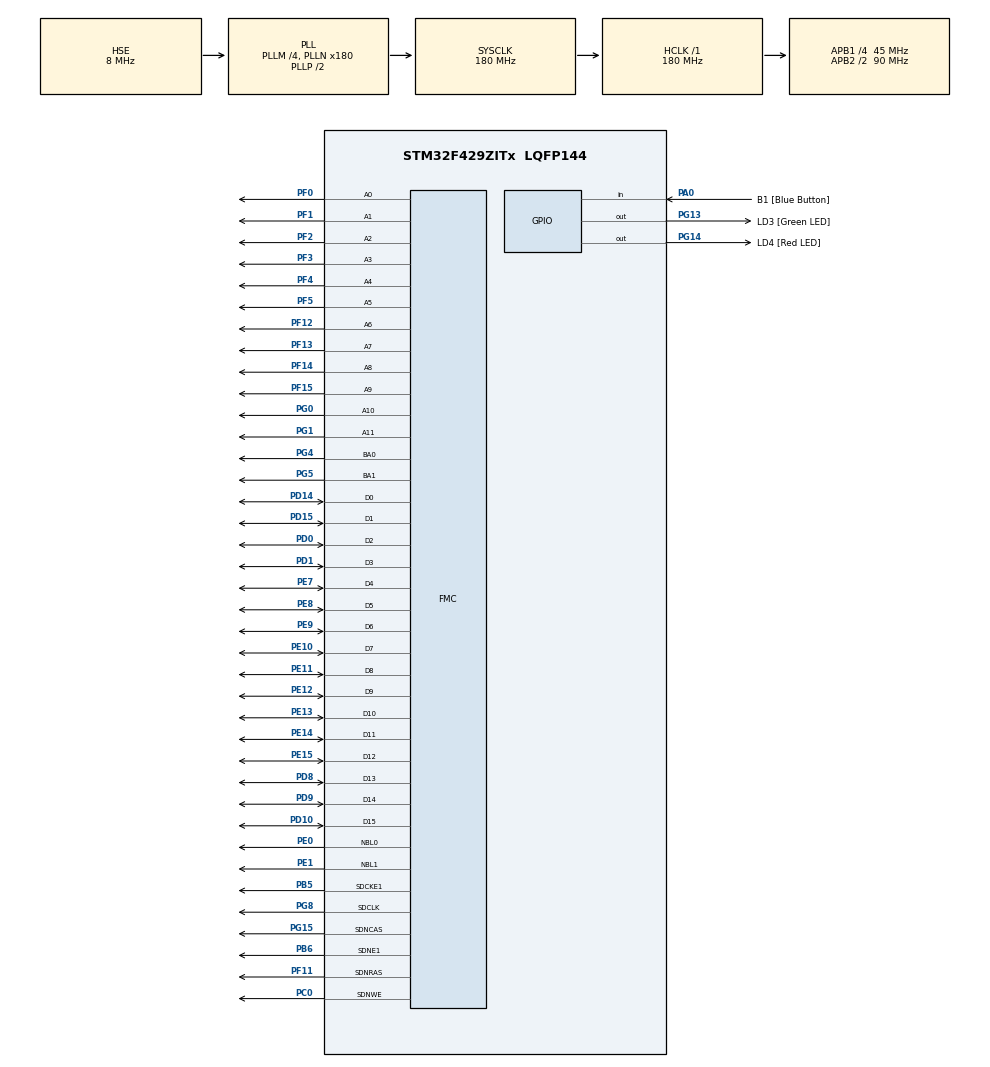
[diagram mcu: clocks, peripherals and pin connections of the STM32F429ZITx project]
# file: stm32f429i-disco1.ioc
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Mcu.Family=STM32F4
SH.FMC_D7_DA7.0=FMC_D7,sd-16b-d1
SH.FMC_A8.0=FMC_A8,12b-sda1
RCC.CortexFreq_Value=180000000
SH.FMC_A0.0=FMC_A0,12b-sda1
SH.FMC_D14_DA14.0=FMC_D14,sd-16b-d1
PG4.Signal=FMC_A14_BA0
PG8.Signal=FMC_SDCLK
PG0.Signal=FMC_A10
SH.FMC_NBL0.0=FMC_NBL0,Sd2ByteEnable1
SH.FMC_D6_DA6.0=FMC_D6,sd-16b-d1
VP_RTC_VS_RTC_Activate.Mode=RTC_Enabled
PA0/WKUP.Signal=GPIO_Input
PC14/OSC32_IN.Mode=LSE-External-Oscillator
SH.FMC_A14_BA0.0=FMC_BA0,FourSdramBanks1
SH.FMC_A11.0=FMC_A11,12b-sda1
SH.FMC_D5_DA5.0=FMC_D5,sd-16b-d1
PG13.Signal=GPIO_Output
PG15.Signal=FMC_SDNCAS
RCC.SYSCLKSource=RCC_SYSCLKSOURCE_PLLCLK
ProjectManager.StackSize=0x400
SH.FMC_A15_BA1.0=FMC_BA1,FourSdramBanks1
SH.FMC_D9_DA9.0=FMC_D9,sd-16b-d1
SH.FMC_A7.0=FMC_A7,12b-sda1
SH.FMC_SDNWE.0=FMC_SDNWE,12b-sda1
RCC.RCC_RTC_Clock_Source=RCC_RTCCLKSOURCE_LSE
PH0/OSC_IN.Mode=HSE-External-Clock-Source
SH.FMC_D11_DA11.0=FMC_D11,sd-16b-d1
RCC.HCLKFreq_Value=180000000
RCC.APB2TimFreq_Value=180000000
PB6.Signal=FMC_SDNE1
SH.FMC_NBL1.0=FMC_NBL1,Sd2ByteEnable1
PH1/OSC_OUT.Signal=RCC_OSC_OUT
PF12.Signal=FMC_A6
PB6.Mode=SdramChipSelect2_1
PD0.Signal=FMC_D2_DA2
PD8.Signal=FMC_D13_DA13
PE1.Signal=FMC_NBL1
SH.FMC_A10.0=FMC_A10,12b-sda1
RCC.AHBFreq_Value=180000000
RCC.HSE_VALUE=8000000
SH.FMC_D8_DA8.0=FMC_D8,sd-16b-d1
SH.FMC_D2_DA2.0=FMC_D2,sd-16b-d1
PE13.Signal=FMC_D10_DA10
PE9.Signal=FMC_D6_DA6
PA14.Mode=Serial_Wire
SH.FMC_A2.0=FMC_A2,12b-sda1
PF11.Signal=FMC_SDNRAS
PB5.Mode=SdramChipSelect2_1
SH.FMC_D1_DA1.0=FMC_D1,sd-16b-d1
PF3.Signal=FMC_A3
SH.FMC_SDNRAS.0=FMC_SDNRAS,12b-sda1
PH1/OSC_OUT.Mode=HSE-External-Clock-Source
PE10.Signal=FMC_D7_DA7
Mcu.Package=LQFP144
SH.FMC_D0_DA0.0=FMC_D0,sd-16b-d1
PC14/OSC32_IN.Signal=RCC_OSC32_IN
SH.FMC_A9.0=FMC_A9,12b-sda1
SH.FMC_D4_DA4.0=FMC_D4,sd-16b-d1
RCC.PLLSAIN=50
PF5.Signal=FMC_A5
SH.FMC_A1.0=FMC_A1,12b-sda1
RCC.APB2CLKDivider=RCC_HCLK_DIV2
SH.FMC_SDCLK.0=FMC_SDCLK,12b-sda1
PF14.Signal=FMC_A8
RCC.APB1TimFreq_Value=90000000
PF0.Signal=FMC_A0
PE7.Signal=FMC_D4_DA4
PD15.Signal=FMC_D1_DA1
SH.FMC_D3_DA3.0=FMC_D3,sd-16b-d1
RCC.PLLSourceVirtual=RCC_PLLSOURCE_HSE
SH.FMC_A4.0=FMC_A4,12b-sda1
PG1.Signal=FMC_A11
PG5.Signal=FMC_A15_BA1
SH.FMC_D10_DA10.0=FMC_D10,sd-16b-d1
PD1.Signal=FMC_D3_DA3
PD9.Signal=FMC_D14_DA14
PC0.Signal=FMC_SDNWE
RCC.APB1CLKDivider=RCC_HCLK_DIV4
PG13.GPIO_Label=LD3 [Green LED]
PD10.Signal=FMC_D15_DA15
PA13.Signal=SYS_JTMS-SWDIO
SH.FMC_A3.0=FMC_A3,12b-sda1
ProjectManager.TargetToolchain=STM32CubeIDE
SH.FMC_D15_DA15.0=FMC_D15,sd-16b-d1
SH.FMC_D13_DA13.0=FMC_D13,sd-16b-d1
PF2.Signal=FMC_A2
PE11.Signal=FMC_D8_DA8
PG14.Signal=GPIO_Output
board=custom
RCC.VCOOutputFreq_Value=360000000
PH0/OSC_IN.Signal=RCC_OSC_IN
SH.FMC_A6.0=FMC_A6,12b-sda1
RCC.APB2Freq_Value=90000000
PE14.Signal=FMC_D11_DA11
PE15.Signal=FMC_D12_DA12
PE8.Signal=FMC_D5_DA5
PA0/WKUP.GPIO_Label=B1 [Blue Button]
SH.FMC_D12_DA12.0=FMC_D12,sd-16b-d1
PF15.Signal=FMC_A9
PF13.Signal=FMC_A7
PF1.Signal=FMC_A1
PA13.Mode=Serial_Wire
PG14.GPIO_Label=LD4 [Red LED]
SH.FMC_SDNCAS.0=FMC_SDNCAS,12b-sda1
Mcu.Name=STM32F429ZITx
PE0.Signal=FMC_NBL0
PE12.Signal=FMC_D9_DA9
PD14.Signal=FMC_D0_DA0
RCC.48MHZClocksFreq_Value=90000000
RCC.SYSCLKFreq_VALUE=180000000
PB5.Signal=FMC_SDCKE1
PC15/OSC32_OUT.Mode=LSE-External-Oscillator
SH.FMC_A5.0=FMC_A5,12b-sda1
PA14.Signal=SYS_JTCK-SWCLK
ProjectManager.HeapSize=0x200
RCC.HSI_VALUE=16000000
NVIC.PriorityGroup=NVIC_PRIORITYGROUP_4
RCC.PLLM=4
RCC.PLLN=180
PC15/OSC32_OUT.Signal=RCC_OSC32_OUT
PF4.Signal=FMC_A4
RCC.APB1Freq_Value=45000000

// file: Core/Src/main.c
/* USER CODE BEGIN Header */
/**
  ******************************************************************************
  * @file           : main.c
  * @brief          : Main program body
  ******************************************************************************
  * @attention
  *
  * <h2><center>&copy; Copyright (c) 2021 STMicroelectronics.
  * All rights reserved.</center></h2>
  *
  * This software component is licensed by ST under BSD 3-Clause license,
  * the "License"; You may not use this file except in compliance with the
  * License. You may obtain a copy of the License at:
  *                        opensource.org/licenses/BSD-3-Clause
  *
  ******************************************************************************
  */
/* USER CODE END Header */
#include "main.h"

/* USER CODE BEGIN Includes */

#include "myos.h"
#include "uileds_leds.h"
#include "uibuttons_buttons.h"

/* USER CODE END Includes */

RTC_HandleTypeDef hrtc;

SDRAM_HandleTypeDef hsdram1;

void SystemClock_Config(void);
static void MX_GPIO_Init(void);
static void MX_FMC_Init(void);
static void MX_RTC_Init(void);

int main(void)
{

  /* MCU Configuration--------------------------------------------------------*/

  /* Reset of all peripherals, Initializes the Flash interface and the Systick. */
  HAL_Init();

  /* Configure the system clock */
  SystemClock_Config();

  /* Initialize all configured peripherals */
  MX_GPIO_Init();
  MX_FMC_Init();
  MX_RTC_Init();
  /* USER CODE BEGIN 2 */

  myos_module_init();
  uileds_leds_module_init();
  uibuttons_buttons_module_init();

  /* USER CODE END 2 */

  /* Infinite loop */
  /* USER CODE BEGIN WHILE */
  while (1)
  {
	  process_run();
    /* USER CODE END WHILE */

  }
}

void SystemClock_Config(void)
{
  RCC_OscInitTypeDef RCC_OscInitStruct = {0};
  RCC_ClkInitTypeDef RCC_ClkInitStruct = {0};
  RCC_PeriphCLKInitTypeDef PeriphClkInitStruct = {0};

  /** Configure the main internal regulator output voltage
  */
  __HAL_RCC_PWR_CLK_ENABLE();
  __HAL_PWR_VOLTAGESCALING_CONFIG(PWR_REGULATOR_VOLTAGE_SCALE1);
  /** Initializes the RCC Oscillators according to the specified parameters
  * in the RCC_OscInitTypeDef structure.
  */
  RCC_OscInitStruct.OscillatorType = RCC_OSCILLATORTYPE_HSE|RCC_OSCILLATORTYPE_LSE;
  RCC_OscInitStruct.HSEState = RCC_HSE_BYPASS;
  RCC_OscInitStruct.LSEState = RCC_LSE_ON;
  RCC_OscInitStruct.PLL.PLLState = RCC_PLL_ON;
  RCC_OscInitStruct.PLL.PLLSource = RCC_PLLSOURCE_HSE;
  RCC_OscInitStruct.PLL.PLLM = 4;
  RCC_OscInitStruct.PLL.PLLN = 180;
  RCC_OscInitStruct.PLL.PLLP = RCC_PLLP_DIV2;
  RCC_OscInitStruct.PLL.PLLQ = 4;
  if (HAL_RCC_OscConfig(&RCC_OscInitStruct) != HAL_OK)
  {
    Error_Handler();
  }
  /** Activate the Over-Drive mode
  */
  if (HAL_PWREx_EnableOverDrive() != HAL_OK)
  {
    Error_Handler();
  }
  /** Initializes the CPU, AHB and APB buses clocks
  */
  RCC_ClkInitStruct.ClockType = RCC_CLOCKTYPE_HCLK|RCC_CLOCKTYPE_SYSCLK
                              |RCC_CLOCKTYPE_PCLK1|RCC_CLOCKTYPE_PCLK2;
  RCC_ClkInitStruct.SYSCLKSource = RCC_SYSCLKSOURCE_PLLCLK;
  RCC_ClkInitStruct.AHBCLKDivider = RCC_SYSCLK_DIV1;
  RCC_ClkInitStruct.APB1CLKDivider = RCC_HCLK_DIV4;
  RCC_ClkInitStruct.APB2CLKDivider = RCC_HCLK_DIV2;

  if (HAL_RCC_ClockConfig(&RCC_ClkInitStruct, FLASH_LATENCY_5) != HAL_OK)
  {
    Error_Handler();
  }
  PeriphClkInitStruct.PeriphClockSelection = RCC_PERIPHCLK_RTC;
  PeriphClkInitStruct.RTCClockSelection = RCC_RTCCLKSOURCE_LSE;
  if (HAL_RCCEx_PeriphCLKConfig(&PeriphClkInitStruct) != HAL_OK)
  {
    Error_Handler();
  }
}

static void MX_RTC_Init(void)
{

  /** Initialize RTC Only
  */
  hrtc.Instance = RTC;
  hrtc.Init.HourFormat = RTC_HOURFORMAT_24;
  hrtc.Init.AsynchPrediv = 127;
  hrtc.Init.SynchPrediv = 255;
  hrtc.Init.OutPut = RTC_OUTPUT_DISABLE;
  hrtc.Init.OutPutPolarity = RTC_OUTPUT_POLARITY_HIGH;
  hrtc.Init.OutPutType = RTC_OUTPUT_TYPE_OPENDRAIN;
  if (HAL_RTC_Init(&hrtc) != HAL_OK)
  {
    Error_Handler();
  }

}

/* FMC initialization function */
static void MX_FMC_Init(void)
{

  FMC_SDRAM_TimingTypeDef SdramTiming = {0};

  /** Perform the SDRAM1 memory initialization sequence
  */
  hsdram1.Instance = FMC_SDRAM_DEVICE;
  /* hsdram1.Init */
  hsdram1.Init.SDBank = FMC_SDRAM_BANK2;
  hsdram1.Init.ColumnBitsNumber = FMC_SDRAM_COLUMN_BITS_NUM_8;
  hsdram1.Init.RowBitsNumber = FMC_SDRAM_ROW_BITS_NUM_12;
  hsdram1.Init.MemoryDataWidth = FMC_SDRAM_MEM_BUS_WIDTH_16;
  hsdram1.Init.InternalBankNumber = FMC_SDRAM_INTERN_BANKS_NUM_4;
  hsdram1.Init.CASLatency = FMC_SDRAM_CAS_LATENCY_1;
  hsdram1.Init.WriteProtection = FMC_SDRAM_WRITE_PROTECTION_DISABLE;
  hsdram1.Init.SDClockPeriod = FMC_SDRAM_CLOCK_DISABLE;
  hsdram1.Init.ReadBurst = FMC_SDRAM_RBURST_DISABLE;
  hsdram1.Init.ReadPipeDelay = FMC_SDRAM_RPIPE_DELAY_0;
  /* SdramTiming */
  SdramTiming.LoadToActiveDelay = 16;
  SdramTiming.ExitSelfRefreshDelay = 16;
  SdramTiming.SelfRefreshTime = 16;
  SdramTiming.RowCycleDelay = 16;
  SdramTiming.WriteRecoveryTime = 16;
  SdramTiming.RPDelay = 16;
  SdramTiming.RCDDelay = 16;

  if (HAL_SDRAM_Init(&hsdram1, &SdramTiming) != HAL_OK)
  {
    Error_Handler( );
  }

}

static void MX_GPIO_Init(void)
{
  GPIO_InitTypeDef GPIO_InitStruct = {0};

  /* GPIO Ports Clock Enable */
  __HAL_RCC_GPIOC_CLK_ENABLE();
  __HAL_RCC_GPIOF_CLK_ENABLE();
  __HAL_RCC_GPIOH_CLK_ENABLE();
  __HAL_RCC_GPIOA_CLK_ENABLE();
  __HAL_RCC_GPIOG_CLK_ENABLE();
  __HAL_RCC_GPIOE_CLK_ENABLE();
  __HAL_RCC_GPIOD_CLK_ENABLE();
  __HAL_RCC_GPIOB_CLK_ENABLE();

  /*Configure GPIO pin Output Level */
  HAL_GPIO_WritePin(GPIOG, LD3_Pin|LD4_Pin, GPIO_PIN_RESET);

  /*Configure GPIO pin : B1_Pin */
  GPIO_InitStruct.Pin = B1_Pin;
  GPIO_InitStruct.Mode = GPIO_MODE_INPUT;
  GPIO_InitStruct.Pull = GPIO_NOPULL;
  HAL_GPIO_Init(B1_GPIO_Port, &GPIO_InitStruct);

  /*Configure GPIO pins : LD3_Pin LD4_Pin */
  GPIO_InitStruct.Pin = LD3_Pin|LD4_Pin;
  GPIO_InitStruct.Mode = GPIO_MODE_OUTPUT_PP;
  GPIO_InitStruct.Pull = GPIO_NOPULL;
  GPIO_InitStruct.Speed = GPIO_SPEED_FREQ_LOW;
  HAL_GPIO_Init(GPIOG, &GPIO_InitStruct);

}

void Error_Handler(void)
{
  __disable_irq();
  while (1)
  {
  }
}

/************************ (C) COPYRIGHT STMicroelectronics *****END OF FILE****/
